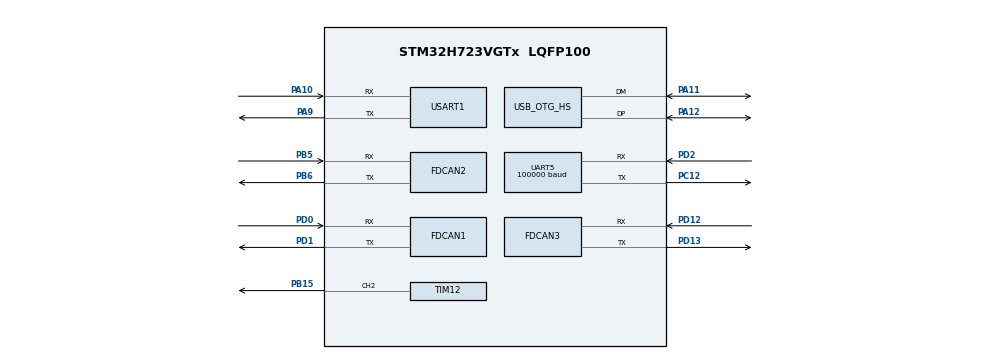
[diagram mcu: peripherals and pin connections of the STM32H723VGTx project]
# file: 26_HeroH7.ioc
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CORTEX_M7.default_mode_Activation=0
Dma.Request0=UART5_RX
Dma.Request1=USART1_RX
Dma.Request2=USART1_TX
Dma.UART5_RX.0.Direction=DMA_PERIPH_TO_MEMORY
Dma.UART5_RX.0.EventEnable=DISABLE
Dma.UART5_RX.0.FIFOMode=DMA_FIFOMODE_DISABLE
Dma.UART5_RX.0.Instance=DMA1_Stream4
Dma.UART5_RX.0.MemDataAlignment=DMA_MDATAALIGN_BYTE
Dma.UART5_RX.0.MemInc=DMA_MINC_ENABLE
Dma.UART5_RX.0.Mode=DMA_NORMAL
Dma.UART5_RX.0.PeriphDataAlignment=DMA_PDATAALIGN_BYTE
Dma.UART5_RX.0.PeriphInc=DMA_PINC_DISABLE
Dma.UART5_RX.0.Polarity=HAL_DMAMUX_REQ_GEN_RISING
Dma.UART5_RX.0.Priority=DMA_PRIORITY_LOW
Dma.UART5_RX.0.RequestNumber=1
Dma.UART5_RX.0.SignalID=NONE
Dma.UART5_RX.0.SyncEnable=DISABLE
Dma.UART5_RX.0.SyncPolarity=HAL_DMAMUX_SYNC_NO_EVENT
Dma.UART5_RX.0.SyncRequestNumber=1
Dma.UART5_RX.0.SyncSignalID=NONE
Dma.USART1_RX.1.Direction=DMA_PERIPH_TO_MEMORY
Dma.USART1_RX.1.EventEnable=DISABLE
Dma.USART1_RX.1.FIFOMode=DMA_FIFOMODE_DISABLE
Dma.USART1_RX.1.Instance=DMA1_Stream1
Dma.USART1_RX.1.MemDataAlignment=DMA_MDATAALIGN_BYTE
Dma.USART1_RX.1.MemInc=DMA_MINC_ENABLE
Dma.USART1_RX.1.Mode=DMA_NORMAL
Dma.USART1_RX.1.PeriphDataAlignment=DMA_PDATAALIGN_BYTE
Dma.USART1_RX.1.PeriphInc=DMA_PINC_DISABLE
Dma.USART1_RX.1.Polarity=HAL_DMAMUX_REQ_GEN_RISING
Dma.USART1_RX.1.Priority=DMA_PRIORITY_HIGH
Dma.USART1_RX.1.RequestNumber=1
Dma.USART1_RX.1.SignalID=NONE
Dma.USART1_RX.1.SyncEnable=DISABLE
Dma.USART1_RX.1.SyncPolarity=HAL_DMAMUX_SYNC_NO_EVENT
Dma.USART1_RX.1.SyncRequestNumber=1
Dma.USART1_RX.1.SyncSignalID=NONE
Dma.USART1_TX.2.Direction=DMA_MEMORY_TO_PERIPH
Dma.USART1_TX.2.EventEnable=DISABLE
Dma.USART1_TX.2.FIFOMode=DMA_FIFOMODE_DISABLE
Dma.USART1_TX.2.Instance=DMA1_Stream2
Dma.USART1_TX.2.MemDataAlignment=DMA_MDATAALIGN_BYTE
Dma.USART1_TX.2.MemInc=DMA_MINC_ENABLE
Dma.USART1_TX.2.Mode=DMA_NORMAL
Dma.USART1_TX.2.PeriphDataAlignment=DMA_PDATAALIGN_BYTE
Dma.USART1_TX.2.PeriphInc=DMA_PINC_DISABLE
Dma.USART1_TX.2.Polarity=HAL_DMAMUX_REQ_GEN_RISING
Dma.USART1_TX.2.Priority=DMA_PRIORITY_HIGH
Dma.USART1_TX.2.RequestNumber=1
Dma.USART1_TX.2.SignalID=NONE
Dma.USART1_TX.2.SyncEnable=DISABLE
Dma.USART1_TX.2.SyncPolarity=HAL_DMAMUX_SYNC_NO_EVENT
Dma.USART1_TX.2.SyncRequestNumber=1
Dma.USART1_TX.2.SyncSignalID=NONE
FDCAN1.CalculateBaudRateNominal=1000000
FDCAN1.CalculateTimeBitNominal=1000
FDCAN1.CalculateTimeQuantumNominal=25.0
FDCAN1.DataPrescaler=3
FDCAN1.DataSyncJumpWidth=10
FDCAN1.DataTimeSeg1=29
FDCAN1.DataTimeSeg2=10
FDCAN1.ExtFiltersNbr=16
FDCAN1.NominalPrescaler=3
FDCAN1.NominalSyncJumpWidth=10
FDCAN1.NominalTimeSeg1=29
FDCAN1.NominalTimeSeg2=10
FDCAN1.ProtocolException=DISABLE
FDCAN1.RxBuffersNbr=2
FDCAN1.RxFifo0ElmtsNbr=16
FDCAN1.RxFifo1ElmtsNbr=32
FDCAN1.StdFiltersNbr=16
FDCAN1.TxBuffersNbr=8
FDCAN1.TxEventsNbr=8
FDCAN1.TxFifoQueueElmtsNbr=32
FDCAN2.CalculateBaudRateNominal=1000000
FDCAN2.CalculateTimeBitNominal=1000
FDCAN2.CalculateTimeQuantumNominal=25.0
FDCAN2.DataPrescaler=3
FDCAN2.DataSyncJumpWidth=10
FDCAN2.DataTimeSeg1=29
FDCAN2.DataTimeSeg2=10
FDCAN2.ExtFiltersNbr=4
FDCAN2.MessageRAMOffset=854
FDCAN2.NominalPrescaler=3
FDCAN2.NominalSyncJumpWidth=10
FDCAN2.NominalTimeSeg1=29
FDCAN2.NominalTimeSeg2=10
FDCAN2.RxBuffersNbr=2
FDCAN2.RxFifo0ElmtsNbr=16
FDCAN2.RxFifo1ElmtsNbr=32
FDCAN2.StdFiltersNbr=16
FDCAN2.TxBuffersNbr=8
FDCAN2.TxEventsNbr=8
FDCAN2.TxFifoQueueElmtsNbr=32
FDCAN3.CalculateBaudRateNominal=1000000
FDCAN3.CalculateTimeBitNominal=1000
FDCAN3.CalculateTimeQuantumNominal=25.0
FDCAN3.DataPrescaler=3
FDCAN3.DataSyncJumpWidth=10
FDCAN3.DataTimeSeg1=29
FDCAN3.DataTimeSeg2=10
FDCAN3.ExtFiltersNbr=16
FDCAN3.MessageRAMOffset=1708
FDCAN3.NominalPrescaler=3
FDCAN3.NominalSyncJumpWidth=10
FDCAN3.NominalTimeSeg1=29
FDCAN3.NominalTimeSeg2=10
FDCAN3.RxBuffersNbr=2
FDCAN3.RxFifo0ElmtsNbr=16
FDCAN3.RxFifo1ElmtsNbr=32
FDCAN3.StdFiltersNbr=16
FDCAN3.TxBuffersNbr=8
FDCAN3.TxEventsNbr=8
FDCAN3.TxFifoQueueElmtsNbr=32
FREERTOS.Tasks01=defaultTask,24,128,StartDefaultTask,Default,NULL,Static,defaultTaskBuffer,defaultTaskControlBlock;Chasis_Task,32,512,chassis_task,As external,NULL,Static,Chasis_TaskBuffer,Chasis_TaskControlBlock;Gimbal_Task,32,512,gimbal_task,As external,NULL,Static,Gimbal_TaskBuffer,Gimbal_TaskControlBlock;Shoot_Task,32,512,shoot_task,As external,NULL,Static,Shoot_TaskBuffer,Shoot_TaskControlBlock
Mcu.Family=STM32H7
Mcu.Name=STM32H723VGTx
Mcu.Package=LQFP100
NVIC.DMA1_Stream1_IRQn=true\:5\:0\:false\:false\:true\:true\:false\:true\:true
NVIC.DMA1_Stream2_IRQn=true\:5\:0\:false\:false\:true\:true\:false\:true\:true
NVIC.DMA1_Stream4_IRQn=true\:0\:0\:false\:false\:true\:false\:false\:true\:true
NVIC.FDCAN1_IT0_IRQn=true\:5\:0\:false\:false\:true\:true\:true\:true\:true
NVIC.FDCAN1_IT1_IRQn=true\:5\:0\:false\:false\:true\:true\:true\:true\:true
NVIC.FDCAN2_IT0_IRQn=true\:5\:0\:false\:false\:true\:true\:true\:true\:true
NVIC.FDCAN2_IT1_IRQn=true\:5\:0\:false\:false\:true\:true\:true\:true\:true
NVIC.FDCAN3_IT0_IRQn=true\:5\:0\:false\:false\:true\:true\:true\:true\:true
NVIC.FDCAN3_IT1_IRQn=true\:5\:0\:false\:false\:true\:true\:true\:true\:true
NVIC.OTG_HS_IRQn=true\:5\:0\:false\:false\:true\:true\:true\:true\:true
NVIC.PriorityGroup=NVIC_PRIORITYGROUP_4
NVIC.TIM6_DAC_IRQn=true\:15\:0\:false\:false\:true\:false\:false\:true\:true
NVIC.TimeBase=TIM6_DAC_IRQn
NVIC.TimeBaseIP=TIM6
NVIC.UART5_IRQn=true\:5\:0\:false\:false\:true\:true\:true\:true\:true
NVIC.USART1_IRQn=true\:5\:0\:false\:false\:true\:true\:true\:true\:true
PA10.Mode=Asynchronous
PA10.Signal=USART1_RX
PA11.Mode=Device_Only_FS
PA11.Signal=USB_OTG_HS_DM
PA12.Mode=Device_Only_FS
PA12.Signal=USB_OTG_HS_DP
PA9.Mode=Asynchronous
PA9.Signal=USART1_TX
PB15.Signal=S_TIM12_CH2
PB5.Mode=FDCAN_Activate
PB5.Signal=FDCAN2_RX
PB6.Mode=FDCAN_Activate
PB6.Signal=FDCAN2_TX
PC12.Mode=Asynchronous
PC12.Signal=UART5_TX
PD0.Mode=FDCAN_Activate
PD0.Signal=FDCAN1_RX
PD1.Mode=FDCAN_Activate
PD1.Signal=FDCAN1_TX
PD12.Mode=FDCAN_Activate
PD12.Signal=FDCAN3_RX
PD13.Mode=FDCAN_Activate
PD13.Signal=FDCAN3_TX
PD2.Mode=Asynchronous
PD2.Signal=UART5_RX
PH0-OSC_IN.Mode=HSE-External-Oscillator
PH0-OSC_IN.Signal=RCC_OSC_IN
PH1-OSC_OUT.Mode=HSE-External-Oscillator
PH1-OSC_OUT.Signal=RCC_OSC_OUT
ProjectManager.HeapSize=0x200
ProjectManager.StackSize=0x400
ProjectManager.TargetToolchain=MDK-ARM V5.32
RCC.ADCFreq_Value=48375000
RCC.APB1Freq_Value=120000000
RCC.APB2Freq_Value=120000000
RCC.APB3Freq_Value=120000000
RCC.APB4Freq_Value=120000000
RCC.CortexFreq_Value=240000000
RCC.D1PPRE=RCC_APB3_DIV2
RCC.D2PPRE1=RCC_APB1_DIV2
RCC.D2PPRE2=RCC_APB2_DIV2
RCC.D3PPRE=RCC_APB4_DIV2
RCC.DIVM1=2
RCC.DIVN1=20
RCC.DIVP1=1
RCC.HCLKFreq_Value=240000000
RCC.HSE_VALUE=24000000
RCC.PLL2FRACN=0
RCC.PLL3FRACN=0
RCC.PLLFRACN=0
RCC.PLLSourceVirtual=RCC_PLLSOURCE_HSE
RCC.SYSCLKFreq_VALUE=240000000
RCC.SYSCLKSource=RCC_SYSCLKSOURCE_PLLCLK
RCC.USBCLockSelection=RCC_USBCLKSOURCE_HSI48
RCC.USBFreq_Value=48000000
SH.S_TIM12_CH2.0=TIM12_CH2,PWM Generation2 CH2
TIM12.AutoReloadPreload=TIM_AUTORELOAD_PRELOAD_ENABLE
TIM12.Channel-PWM\ Generation2\ CH2=TIM_CHANNEL_2
TIM12.Period=2000-1
TIM12.Prescaler=24-1
TIM12.Pulse-PWM\ Generation2\ CH2=1000
UART5.BaudRate=100000
UART5.Parity=PARITY_EVEN
UART5.StopBits=UART_STOPBITS_2
UART5.WordLength=WORDLENGTH_9B
USART1.VirtualMode-Asynchronous=VM_ASYNC
USB_DEVICE.CLASS_NAME_HS=CDC
USB_DEVICE.VirtualMode=Cdc
USB_DEVICE.VirtualModeHS=Cdc_HS
USB_OTG_HS.VirtualMode-Device_Only_FS=Device_Only_FS
VP_FREERTOS_VS_CMSIS_V2.Mode=CMSIS_V2
VP_MEMORYMAP_VS_MEMORYMAP.Mode=CurAppReg
VP_SYS_VS_tim6.Mode=TIM6
VP_TIM12_VS_ClockSourceINT.Mode=Internal
VP_USB_DEVICE_VS_USB_DEVICE_CDC_HS.Mode=CDC_HS
board=custom

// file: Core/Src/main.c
/* USER CODE BEGIN Header */
/**
 ******************************************************************************
 * @file           : main.c
 * @brief          : Main program body
 ******************************************************************************
 * @attention
 *
 * Copyright (c) 2025 STMicroelectronics.
 * All rights reserved.
 *
 * This software is licensed under terms that can be found in the LICENSE file
 * in the root directory of this software component.
 * If no LICENSE file comes with this software, it is provided AS-IS.
 *
 ******************************************************************************
 */
/* USER CODE END Header */
#include "main.h"
#include "cmsis_os.h"
#include "dma.h"
#include "fdcan.h"
#include "tim.h"
#include "usart.h"
#include "usb_device.h"
#include "gpio.h"

void SystemClock_Config(void);
void MX_FREERTOS_Init(void);
/* USER CODE BEGIN PFP */
void BSP_All_Init(void);
/* USER CODE END PFP */

int main(void)
{

  /* MCU Configuration--------------------------------------------------------*/

  /* Reset of all peripherals, Initializes the Flash interface and the Systick. */
  HAL_Init();

  /* Configure the system clock */
  SystemClock_Config();

  /* Initialize all configured peripherals */
  MX_GPIO_Init();
  MX_DMA_Init();
  MX_TIM12_Init();
  MX_UART5_Init();
  MX_FDCAN1_Init();
  MX_USART1_UART_Init();
  MX_FDCAN2_Init();
  MX_FDCAN3_Init();
  /* USER CODE BEGIN 2 */
	BSP_All_Init();
  /* USER CODE END 2 */

  /* Init scheduler */
  osKernelInitialize();  /* Call init function for freertos objects (in cmsis_os2.c) */
  MX_FREERTOS_Init();

  /* Start scheduler */
  osKernelStart();

  /* We should never get here as control is now taken by the scheduler */

  /* Infinite loop */
	while (1)
	{

	}
}

void SystemClock_Config(void)
{
  RCC_OscInitTypeDef RCC_OscInitStruct = {0};
  RCC_ClkInitTypeDef RCC_ClkInitStruct = {0};

  /** Supply configuration update enable
  */
  HAL_PWREx_ConfigSupply(PWR_LDO_SUPPLY);

  /** Configure the main internal regulator output voltage
  */
  __HAL_PWR_VOLTAGESCALING_CONFIG(PWR_REGULATOR_VOLTAGE_SCALE0);

  while(!__HAL_PWR_GET_FLAG(PWR_FLAG_VOSRDY)) {}

  /** Initializes the RCC Oscillators according to the specified parameters
  * in the RCC_OscInitTypeDef structure.
  */
  RCC_OscInitStruct.OscillatorType = RCC_OSCILLATORTYPE_HSI48|RCC_OSCILLATORTYPE_HSE;
  RCC_OscInitStruct.HSEState = RCC_HSE_ON;
  RCC_OscInitStruct.HSI48State = RCC_HSI48_ON;
  RCC_OscInitStruct.PLL.PLLState = RCC_PLL_ON;
  RCC_OscInitStruct.PLL.PLLSource = RCC_PLLSOURCE_HSE;
  RCC_OscInitStruct.PLL.PLLM = 2;
  RCC_OscInitStruct.PLL.PLLN = 20;
  RCC_OscInitStruct.PLL.PLLP = 1;
  RCC_OscInitStruct.PLL.PLLQ = 2;
  RCC_OscInitStruct.PLL.PLLR = 2;
  RCC_OscInitStruct.PLL.PLLRGE = RCC_PLL1VCIRANGE_3;
  RCC_OscInitStruct.PLL.PLLVCOSEL = RCC_PLL1VCOWIDE;
  RCC_OscInitStruct.PLL.PLLFRACN = 0;
  if (HAL_RCC_OscConfig(&RCC_OscInitStruct) != HAL_OK)
  {
    Error_Handler();
  }

  /** Initializes the CPU, AHB and APB buses clocks
  */
  RCC_ClkInitStruct.ClockType = RCC_CLOCKTYPE_HCLK|RCC_CLOCKTYPE_SYSCLK
                              |RCC_CLOCKTYPE_PCLK1|RCC_CLOCKTYPE_PCLK2
                              |RCC_CLOCKTYPE_D3PCLK1|RCC_CLOCKTYPE_D1PCLK1;
  RCC_ClkInitStruct.SYSCLKSource = RCC_SYSCLKSOURCE_PLLCLK;
  RCC_ClkInitStruct.SYSCLKDivider = RCC_SYSCLK_DIV1;
  RCC_ClkInitStruct.AHBCLKDivider = RCC_HCLK_DIV1;
  RCC_ClkInitStruct.APB3CLKDivider = RCC_APB3_DIV2;
  RCC_ClkInitStruct.APB1CLKDivider = RCC_APB1_DIV2;
  RCC_ClkInitStruct.APB2CLKDivider = RCC_APB2_DIV2;
  RCC_ClkInitStruct.APB4CLKDivider = RCC_APB4_DIV2;

  if (HAL_RCC_ClockConfig(&RCC_ClkInitStruct, FLASH_LATENCY_3) != HAL_OK)
  {
    Error_Handler();
  }
}

/* USER CODE BEGIN 4 */
void BSP_All_Init(void)
{
	dbus_uart_init();
	bsp_can_init();
	Beep(200);
}
/* USER CODE END 4 */

void HAL_TIM_PeriodElapsedCallback(TIM_HandleTypeDef *htim)
{
  if (htim->Instance == TIM6)
  {
    HAL_IncTick();
  }
}

void Error_Handler(void)
{
	__disable_irq();
	while (1)
	{
	}
}

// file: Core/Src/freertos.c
/* USER CODE BEGIN Header */
/**
  ******************************************************************************
  * File Name          : freertos.c
  * Description        : Code for freertos applications
  ******************************************************************************
  * @attention
  *
  * Copyright (c) 2025 STMicroelectronics.
  * All rights reserved.
  *
  * This software is licensed under terms that can be found in the LICENSE file
  * in the root directory of this software component.
  * If no LICENSE file comes with this software, it is provided AS-IS.
  *
  ******************************************************************************
  */
/* USER CODE END Header */

#include "FreeRTOS.h"
#include "task.h"
#include "main.h"
#include "cmsis_os.h"

typedef StaticTask_t osStaticThreadDef_t;

/* Definitions for defaultTask */
osThreadId_t defaultTaskHandle;
uint32_t defaultTaskBuffer[ 128 ];
osStaticThreadDef_t defaultTaskControlBlock;
const osThreadAttr_t defaultTask_attributes = {
  .name = "defaultTask",
  .cb_mem = &defaultTaskControlBlock,
  .cb_size = sizeof(defaultTaskControlBlock),
  .stack_mem = &defaultTaskBuffer[0],
  .stack_size = sizeof(defaultTaskBuffer),
  .priority = (osPriority_t) osPriorityNormal,
};
/* Definitions for Chasis_Task */
osThreadId_t Chasis_TaskHandle;
uint32_t Chasis_TaskBuffer[ 512 ];
osStaticThreadDef_t Chasis_TaskControlBlock;
const osThreadAttr_t Chasis_Task_attributes = {
  .name = "Chasis_Task",
  .cb_mem = &Chasis_TaskControlBlock,
  .cb_size = sizeof(Chasis_TaskControlBlock),
  .stack_mem = &Chasis_TaskBuffer[0],
  .stack_size = sizeof(Chasis_TaskBuffer),
  .priority = (osPriority_t) osPriorityAboveNormal,
};
/* Definitions for Gimbal_Task */
osThreadId_t Gimbal_TaskHandle;
uint32_t Gimbal_TaskBuffer[ 512 ];
osStaticThreadDef_t Gimbal_TaskControlBlock;
const osThreadAttr_t Gimbal_Task_attributes = {
  .name = "Gimbal_Task",
  .cb_mem = &Gimbal_TaskControlBlock,
  .cb_size = sizeof(Gimbal_TaskControlBlock),
  .stack_mem = &Gimbal_TaskBuffer[0],
  .stack_size = sizeof(Gimbal_TaskBuffer),
  .priority = (osPriority_t) osPriorityAboveNormal,
};
/* Definitions for Shoot_Task */
osThreadId_t Shoot_TaskHandle;
uint32_t Shoot_TaskBuffer[ 512 ];
osStaticThreadDef_t Shoot_TaskControlBlock;
const osThreadAttr_t Shoot_Task_attributes = {
  .name = "Shoot_Task",
  .cb_mem = &Shoot_TaskControlBlock,
  .cb_size = sizeof(Shoot_TaskControlBlock),
  .stack_mem = &Shoot_TaskBuffer[0],
  .stack_size = sizeof(Shoot_TaskBuffer),
  .priority = (osPriority_t) osPriorityAboveNormal,
};

void StartDefaultTask(void *argument);
extern void chassis_task(void *argument);
extern void gimbal_task(void *argument);
extern void shoot_task(void *argument);

extern void MX_USB_DEVICE_Init(void);
void MX_FREERTOS_Init(void); /* (MISRA C 2004 rule 8.1) */

void MX_FREERTOS_Init(void) {

  /* Create the thread(s) */
  /* creation of defaultTask */
  defaultTaskHandle = osThreadNew(StartDefaultTask, NULL, &defaultTask_attributes);

  /* creation of Chasis_Task */
  Chasis_TaskHandle = osThreadNew(chassis_task, NULL, &Chasis_Task_attributes);

  /* creation of Gimbal_Task */
  Gimbal_TaskHandle = osThreadNew(gimbal_task, NULL, &Gimbal_Task_attributes);

  /* creation of Shoot_Task */
  Shoot_TaskHandle = osThreadNew(shoot_task, NULL, &Shoot_Task_attributes);

}

void StartDefaultTask(void *argument)
{
  /* init code for USB_DEVICE */
  MX_USB_DEVICE_Init();
  for(;;)
  {
    osDelay(1);
  }
}
